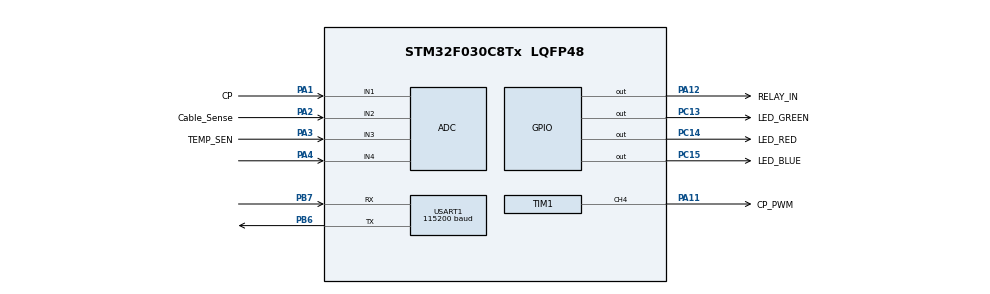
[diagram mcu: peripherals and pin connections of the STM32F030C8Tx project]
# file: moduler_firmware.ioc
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ADC.DMAContinuousRequests=ENABLE
ADC.DiscontinuousConvMode=ENABLE
ADC.ExternalTrigConv=ADC_EXTERNALTRIGCONV_T1_TRGO
ADC.SamplingTime=ADC_SAMPLETIME_239CYCLES_5
Dma.ADC.0.Direction=DMA_PERIPH_TO_MEMORY
Dma.ADC.0.Instance=DMA1_Channel1
Dma.ADC.0.MemDataAlignment=DMA_MDATAALIGN_WORD
Dma.ADC.0.MemInc=DMA_MINC_ENABLE
Dma.ADC.0.Mode=DMA_CIRCULAR
Dma.ADC.0.PeriphDataAlignment=DMA_PDATAALIGN_WORD
Dma.ADC.0.PeriphInc=DMA_PINC_DISABLE
Dma.ADC.0.Priority=DMA_PRIORITY_HIGH
Dma.Request0=ADC
FREERTOS.Tasks01=defaultTask,0,128,StartDefaultTask,Default,NULL,Dynamic,NULL,NULL
FREERTOS.configTOTAL_HEAP_SIZE=4096
FREERTOS.configUSE_NEWLIB_REENTRANT=1
Mcu.Family=STM32F0
Mcu.Name=STM32F030C8Tx
Mcu.Package=LQFP48
NVIC.DMA1_Channel1_IRQn=true\:3\:0\:false\:false\:true\:true\:false\:true\:true
NVIC.TIM3_IRQn=true\:3\:0\:false\:false\:true\:false\:false\:true\:true
NVIC.TimeBase=TIM3_IRQn
NVIC.TimeBaseIP=TIM3
NVIC.USART1_IRQn=true\:3\:0\:false\:false\:true\:true\:true\:true\:true
PA1.GPIO_Label=CP
PA1.Mode=IN1
PA1.Signal=ADC_IN1
PA11.GPIO_Label=CP_PWM
PA11.Signal=S_TIM1_CH4
PA12.GPIO_Label=RELAY_IN
PA12.Signal=GPIO_Output
PA2.GPIO_Label=Cable_Sense
PA2.Mode=IN2
PA2.Signal=ADC_IN2
PA3.GPIO_Label=TEMP_SEN
PA3.Mode=IN3
PA3.Signal=ADC_IN3
PA4.Mode=IN4
PA4.Signal=ADC_IN4
PB6.Mode=Asynchronous
PB6.Signal=USART1_TX
PB7.Mode=Asynchronous
PB7.Signal=USART1_RX
PC13.GPIO_Label=LED_GREEN
PC13.Signal=GPIO_Output
PC14-OSC32_IN.GPIO_Label=LED_RED
PC14-OSC32_IN.Signal=GPIO_Output
PC15-OSC32_OUT.GPIO_Label=LED_BLUE
PC15-OSC32_OUT.Signal=GPIO_Output
ProjectManager.HeapSize=0x200
ProjectManager.StackSize=0x400
ProjectManager.TargetToolchain=STM32CubeIDE
SH.S_TIM1_CH4.0=TIM1_CH4,PWM Generation4 CH4
TIM1.Channel-Output\ Compare1\ No\ Output=TIM_CHANNEL_1
TIM1.Channel-PWM\ Generation4\ CH4=TIM_CHANNEL_4
TIM1.Period=999
TIM1.Prescaler=7
TIM1.Pulse-Output\ Compare1\ No\ Output=150
TIM1.TIM_MasterOutputTrigger=TIM_TRGO_OC1
USART1.BaudRate=115200
USART1.VirtualMode-Asynchronous=VM_ASYNC
VP_FREERTOS_VS_CMSIS_V1.Mode=CMSIS_V1
VP_IWDG_VS_IWDG.Mode=IWDG_Activate
VP_SYS_VS_tim3.Mode=TIM3
VP_TIM1_VS_no_output1.Mode=Output Compare1 No Output
board=custom

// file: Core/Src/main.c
/* USER CODE BEGIN Header */
/**
  ******************************************************************************
  * @file           : main.c
  * @brief          : Main program body
  ******************************************************************************
  * @attention
  *
  * Copyright (c) 2026 STMicroelectronics.
  * All rights reserved.
  *
  * This software is licensed under terms that can be found in the LICENSE file
  * in the root directory of this software component.
  * If no LICENSE file comes with this software, it is provided AS-IS.
  *
  ******************************************************************************
  */
/* USER CODE END Header */
#include "main.h"
#include "cmsis_os.h"

/* USER CODE BEGIN Includes */
#include "app_main.h"
/* USER CODE END Includes */

ADC_HandleTypeDef hadc;
DMA_HandleTypeDef hdma_adc;

IWDG_HandleTypeDef hiwdg;

TIM_HandleTypeDef htim1;

UART_HandleTypeDef huart1;

osThreadId defaultTaskHandle;

void SystemClock_Config(void);
static void MX_GPIO_Init(void);
static void MX_DMA_Init(void);
static void MX_ADC_Init(void);
static void MX_TIM1_Init(void);
static void MX_IWDG_Init(void);
static void MX_USART1_UART_Init(void);
void StartDefaultTask(void const * argument);

int main(void)
{

  /* MCU Configuration--------------------------------------------------------*/

  /* Reset of all peripherals, Initializes the Flash interface and the Systick. */
  HAL_Init();

  /* Configure the system clock */
  SystemClock_Config();

  /* Initialize all configured peripherals */
  MX_GPIO_Init();
  MX_DMA_Init();
  MX_ADC_Init();
  MX_TIM1_Init();
  MX_IWDG_Init();
  MX_USART1_UART_Init();
  /* USER CODE BEGIN 2 */
  App_Init();

  /* USER CODE END 2 */

  /* Create the thread(s) */
  /* definition and creation of defaultTask */
  osThreadDef(defaultTask, StartDefaultTask, osPriorityNormal, 0, 128);
  defaultTaskHandle = osThreadCreate(osThread(defaultTask), NULL);

  /* Start scheduler */
  osKernelStart();

  /* We should never get here as control is now taken by the scheduler */

  /* Infinite loop */
  while (1)
  {

  }
}

void SystemClock_Config(void)
{
  RCC_OscInitTypeDef RCC_OscInitStruct = {0};
  RCC_ClkInitTypeDef RCC_ClkInitStruct = {0};
  RCC_PeriphCLKInitTypeDef PeriphClkInit = {0};

  /** Initializes the RCC Oscillators according to the specified parameters
  * in the RCC_OscInitTypeDef structure.
  */
  RCC_OscInitStruct.OscillatorType = RCC_OSCILLATORTYPE_HSI|RCC_OSCILLATORTYPE_HSI14
                              |RCC_OSCILLATORTYPE_LSI;
  RCC_OscInitStruct.HSIState = RCC_HSI_ON;
  RCC_OscInitStruct.HSI14State = RCC_HSI14_ON;
  RCC_OscInitStruct.HSICalibrationValue = RCC_HSICALIBRATION_DEFAULT;
  RCC_OscInitStruct.HSI14CalibrationValue = 16;
  RCC_OscInitStruct.LSIState = RCC_LSI_ON;
  RCC_OscInitStruct.PLL.PLLState = RCC_PLL_NONE;
  if (HAL_RCC_OscConfig(&RCC_OscInitStruct) != HAL_OK)
  {
    Error_Handler();
  }

  /** Initializes the CPU, AHB and APB buses clocks
  */
  RCC_ClkInitStruct.ClockType = RCC_CLOCKTYPE_HCLK|RCC_CLOCKTYPE_SYSCLK
                              |RCC_CLOCKTYPE_PCLK1;
  RCC_ClkInitStruct.SYSCLKSource = RCC_SYSCLKSOURCE_HSI;
  RCC_ClkInitStruct.AHBCLKDivider = RCC_SYSCLK_DIV1;
  RCC_ClkInitStruct.APB1CLKDivider = RCC_HCLK_DIV1;

  if (HAL_RCC_ClockConfig(&RCC_ClkInitStruct, FLASH_LATENCY_0) != HAL_OK)
  {
    Error_Handler();
  }
  PeriphClkInit.PeriphClockSelection = RCC_PERIPHCLK_USART1;
  PeriphClkInit.Usart1ClockSelection = RCC_USART1CLKSOURCE_PCLK1;
  if (HAL_RCCEx_PeriphCLKConfig(&PeriphClkInit) != HAL_OK)
  {
    Error_Handler();
  }
}

static void MX_ADC_Init(void)
{

  ADC_ChannelConfTypeDef sConfig = {0};

  /** Configure the global features of the ADC (Clock, Resolution, Data Alignment and number of conversion)
  */
  hadc.Instance = ADC1;
  hadc.Init.ClockPrescaler = ADC_CLOCK_ASYNC_DIV1;
  hadc.Init.Resolution = ADC_RESOLUTION_12B;
  hadc.Init.DataAlign = ADC_DATAALIGN_RIGHT;
  hadc.Init.ScanConvMode = ADC_SCAN_DIRECTION_FORWARD;
  hadc.Init.EOCSelection = ADC_EOC_SINGLE_CONV;
  hadc.Init.LowPowerAutoWait = DISABLE;
  hadc.Init.LowPowerAutoPowerOff = DISABLE;
  hadc.Init.ContinuousConvMode = DISABLE;
  hadc.Init.DiscontinuousConvMode = ENABLE;
  hadc.Init.ExternalTrigConv = ADC_EXTERNALTRIGCONV_T1_TRGO;
  hadc.Init.ExternalTrigConvEdge = ADC_EXTERNALTRIGCONVEDGE_RISING;
  hadc.Init.DMAContinuousRequests = ENABLE;
  hadc.Init.Overrun = ADC_OVR_DATA_PRESERVED;
  if (HAL_ADC_Init(&hadc) != HAL_OK)
  {
    Error_Handler();
  }

  /** Configure for the selected ADC regular channel to be converted.
  */
  sConfig.Channel = ADC_CHANNEL_1;
  sConfig.Rank = ADC_RANK_CHANNEL_NUMBER;
  sConfig.SamplingTime = ADC_SAMPLETIME_239CYCLES_5;
  if (HAL_ADC_ConfigChannel(&hadc, &sConfig) != HAL_OK)
  {
    Error_Handler();
  }

  /** Configure for the selected ADC regular channel to be converted.
  */
  sConfig.Channel = ADC_CHANNEL_2;
  if (HAL_ADC_ConfigChannel(&hadc, &sConfig) != HAL_OK)
  {
    Error_Handler();
  }

  /** Configure for the selected ADC regular channel to be converted.
  */
  sConfig.Channel = ADC_CHANNEL_3;
  if (HAL_ADC_ConfigChannel(&hadc, &sConfig) != HAL_OK)
  {
    Error_Handler();
  }

  /** Configure for the selected ADC regular channel to be converted.
  */
  sConfig.Channel = ADC_CHANNEL_4;
  if (HAL_ADC_ConfigChannel(&hadc, &sConfig) != HAL_OK)
  {
    Error_Handler();
  }

}

static void MX_IWDG_Init(void)
{

  hiwdg.Instance = IWDG;
  hiwdg.Init.Prescaler = IWDG_PRESCALER_4;
  hiwdg.Init.Window = 4095;
  hiwdg.Init.Reload = 4095;
  if (HAL_IWDG_Init(&hiwdg) != HAL_OK)
  {
    Error_Handler();
  }

}

static void MX_TIM1_Init(void)
{

  TIM_MasterConfigTypeDef sMasterConfig = {0};
  TIM_OC_InitTypeDef sConfigOC = {0};
  TIM_BreakDeadTimeConfigTypeDef sBreakDeadTimeConfig = {0};

  htim1.Instance = TIM1;
  htim1.Init.Prescaler = 7;
  htim1.Init.CounterMode = TIM_COUNTERMODE_UP;
  htim1.Init.Period = 999;
  htim1.Init.ClockDivision = TIM_CLOCKDIVISION_DIV1;
  htim1.Init.RepetitionCounter = 0;
  htim1.Init.AutoReloadPreload = TIM_AUTORELOAD_PRELOAD_DISABLE;
  if (HAL_TIM_OC_Init(&htim1) != HAL_OK)
  {
    Error_Handler();
  }
  if (HAL_TIM_PWM_Init(&htim1) != HAL_OK)
  {
    Error_Handler();
  }
  sMasterConfig.MasterOutputTrigger = TIM_TRGO_OC1;
  sMasterConfig.MasterSlaveMode = TIM_MASTERSLAVEMODE_DISABLE;
  if (HAL_TIMEx_MasterConfigSynchronization(&htim1, &sMasterConfig) != HAL_OK)
  {
    Error_Handler();
  }
  sConfigOC.OCMode = TIM_OCMODE_TIMING;
  sConfigOC.Pulse = 150;
  sConfigOC.OCPolarity = TIM_OCPOLARITY_HIGH;
  sConfigOC.OCNPolarity = TIM_OCNPOLARITY_HIGH;
  sConfigOC.OCFastMode = TIM_OCFAST_DISABLE;
  sConfigOC.OCIdleState = TIM_OCIDLESTATE_RESET;
  sConfigOC.OCNIdleState = TIM_OCNIDLESTATE_RESET;
  if (HAL_TIM_OC_ConfigChannel(&htim1, &sConfigOC, TIM_CHANNEL_1) != HAL_OK)
  {
    Error_Handler();
  }
  sConfigOC.OCMode = TIM_OCMODE_PWM1;
  sConfigOC.Pulse = 0;
  if (HAL_TIM_PWM_ConfigChannel(&htim1, &sConfigOC, TIM_CHANNEL_4) != HAL_OK)
  {
    Error_Handler();
  }
  sBreakDeadTimeConfig.OffStateRunMode = TIM_OSSR_DISABLE;
  sBreakDeadTimeConfig.OffStateIDLEMode = TIM_OSSI_DISABLE;
  sBreakDeadTimeConfig.LockLevel = TIM_LOCKLEVEL_OFF;
  sBreakDeadTimeConfig.DeadTime = 0;
  sBreakDeadTimeConfig.BreakState = TIM_BREAK_DISABLE;
  sBreakDeadTimeConfig.BreakPolarity = TIM_BREAKPOLARITY_HIGH;
  sBreakDeadTimeConfig.AutomaticOutput = TIM_AUTOMATICOUTPUT_DISABLE;
  if (HAL_TIMEx_ConfigBreakDeadTime(&htim1, &sBreakDeadTimeConfig) != HAL_OK)
  {
    Error_Handler();
  }
  HAL_TIM_MspPostInit(&htim1);

}

static void MX_USART1_UART_Init(void)
{

  huart1.Instance = USART1;
  huart1.Init.BaudRate = 9600;
  huart1.Init.WordLength = UART_WORDLENGTH_8B;
  huart1.Init.StopBits = UART_STOPBITS_1;
  huart1.Init.Parity = UART_PARITY_NONE;
  huart1.Init.Mode = UART_MODE_TX_RX;
  huart1.Init.HwFlowCtl = UART_HWCONTROL_NONE;
  huart1.Init.OverSampling = UART_OVERSAMPLING_16;
  huart1.Init.OneBitSampling = UART_ONE_BIT_SAMPLE_DISABLE;
  huart1.AdvancedInit.AdvFeatureInit = UART_ADVFEATURE_NO_INIT;
  if (HAL_UART_Init(&huart1) != HAL_OK)
  {
    Error_Handler();
  }

}

static void MX_DMA_Init(void)
{

  /* DMA controller clock enable */
  __HAL_RCC_DMA1_CLK_ENABLE();

  /* DMA interrupt init */
  /* DMA1_Channel1_IRQn interrupt configuration */
  HAL_NVIC_SetPriority(DMA1_Channel1_IRQn, 3, 0);
  HAL_NVIC_EnableIRQ(DMA1_Channel1_IRQn);

}

static void MX_GPIO_Init(void)
{
  GPIO_InitTypeDef GPIO_InitStruct = {0};

  /* GPIO Ports Clock Enable */
  __HAL_RCC_GPIOC_CLK_ENABLE();
  __HAL_RCC_GPIOA_CLK_ENABLE();
  __HAL_RCC_GPIOB_CLK_ENABLE();

  /*Configure GPIO pin Output Level */
  HAL_GPIO_WritePin(GPIOC, LED_GREEN_Pin|LED_RED_Pin|LED_BLUE_Pin, GPIO_PIN_RESET);

  /*Configure GPIO pin Output Level */
  HAL_GPIO_WritePin(RELAY_IN_GPIO_Port, RELAY_IN_Pin, GPIO_PIN_RESET);

  /*Configure GPIO pins : LED_GREEN_Pin LED_RED_Pin LED_BLUE_Pin */
  GPIO_InitStruct.Pin = LED_GREEN_Pin|LED_RED_Pin|LED_BLUE_Pin;
  GPIO_InitStruct.Mode = GPIO_MODE_OUTPUT_PP;
  GPIO_InitStruct.Pull = GPIO_NOPULL;
  GPIO_InitStruct.Speed = GPIO_SPEED_FREQ_LOW;
  HAL_GPIO_Init(GPIOC, &GPIO_InitStruct);

  /*Configure GPIO pin : RELAY_IN_Pin */
  GPIO_InitStruct.Pin = RELAY_IN_Pin;
  GPIO_InitStruct.Mode = GPIO_MODE_OUTPUT_PP;
  GPIO_InitStruct.Pull = GPIO_NOPULL;
  GPIO_InitStruct.Speed = GPIO_SPEED_FREQ_LOW;
  HAL_GPIO_Init(RELAY_IN_GPIO_Port, &GPIO_InitStruct);

}

void StartDefaultTask(void const * argument)
{
  for(;;)
  {
    osDelay(1);
  }
}

void HAL_TIM_PeriodElapsedCallback(TIM_HandleTypeDef *htim)
{
  if (htim->Instance == TIM3)
  {
    HAL_IncTick();
  }
}

void Error_Handler(void)
{
  __disable_irq();
  while (1)
  {
  }
}
